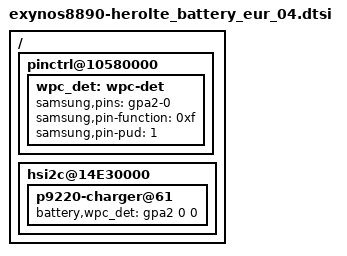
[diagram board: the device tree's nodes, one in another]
/*
 * SAMSUNG UNIVERSAL5433 board device tree source
 *
 * Copyright (c) 2013 Samsung Electronics Co., Ltd.
 *		http://www.samsung.com
 *
 * This program is free software; you can redistribute it and/or modify
 * it under the terms of the GNU General Public License version 2 as
 * published by the Free Software Foundation.
*/

#include "exynos8890-herolte_battery.dtsi"
/ {
	pinctrl@10580000 {
		wpc_det: wpc-det {
			samsung,pins = "gpa2-0";
			samsung,pin-function = <0xf>;
			samsung,pin-pud = <1>;
		};
	};

	hsi2c@14E30000 {
		p9220-charger@61 {
			battery,wpc_det = <&gpa2 0 0>;
		};
	};
};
